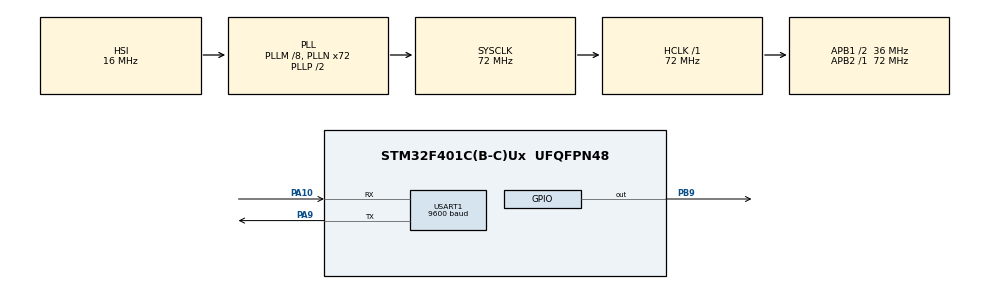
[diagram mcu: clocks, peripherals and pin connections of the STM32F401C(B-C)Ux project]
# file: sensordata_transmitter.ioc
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Mcu.Family=STM32F4
Mcu.Name=STM32F401C(B-C)Ux
Mcu.Package=UFQFPN48
NVIC.PriorityGroup=NVIC_PRIORITYGROUP_4
PA10.Mode=Asynchronous
PA10.Signal=USART1_RX
PA13.Mode=Serial_Wire
PA13.Signal=SYS_JTMS-SWDIO
PA14.Mode=Serial_Wire
PA14.Signal=SYS_JTCK-SWCLK
PA9.Mode=Asynchronous
PA9.Signal=USART1_TX
PB9.Signal=GPIO_Output
ProjectManager.HeapSize=0x200
ProjectManager.StackSize=0x400
ProjectManager.TargetToolchain=STM32CubeIDE
RCC.48MHZClocksFreq_Value=36000000
RCC.AHBFreq_Value=72000000
RCC.APB1CLKDivider=RCC_HCLK_DIV2
RCC.APB1Freq_Value=36000000
RCC.APB1TimFreq_Value=72000000
RCC.APB2Freq_Value=72000000
RCC.APB2TimFreq_Value=72000000
RCC.CortexFreq_Value=72000000
RCC.HCLKFreq_Value=72000000
RCC.HSE_VALUE=25000000
RCC.HSI_VALUE=16000000
RCC.LSE_VALUE=32768
RCC.PLLM=8
RCC.PLLN=72
RCC.SYSCLKFreq_VALUE=72000000
RCC.SYSCLKSource=RCC_SYSCLKSOURCE_PLLCLK
RCC.VCOOutputFreq_Value=144000000
TIM1.Prescaler=71
USART1.BaudRate=9600
USART1.VirtualMode=VM_ASYNC
VP_TIM1_VS_ClockSourceINT.Mode=Internal
board=custom

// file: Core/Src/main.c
/* USER CODE BEGIN Header */
/**
  ******************************************************************************
  * @file           : main.c
  * @brief          : Main program body
  ******************************************************************************
  * @attention
  *
  * Copyright (c) 2024 STMicroelectronics.
  * All rights reserved.
  *
  * This software is licensed under terms that can be found in the LICENSE file
  * in the root directory of this software component.
  * If no LICENSE file comes with this software, it is provided AS-IS.
  *
  ******************************************************************************
  */
/* USER CODE END Header */
#include "main.h"

/* USER CODE BEGIN Includes */
#include <stdio.h>
#include <string.h>
/* USER CODE END Includes */

TIM_HandleTypeDef htim1;

UART_HandleTypeDef huart1;

void SystemClock_Config(void);
static void MX_GPIO_Init(void);
static void MX_TIM1_Init(void);
static void MX_USART1_UART_Init(void);

/* USER CODE BEGIN 0 */
#define DHT11_PORT GPIOB
#define DHT11_PIN GPIO_PIN_9
uint8_t RHI, RHD, TCI, TCD, SUM;
uint32_t pMillis, cMillis;
float tCelsius = 0;
float tFahrenheit = 0;
float RH = 0;
uint8_t TFI = 0;
uint8_t TFD = 0;
char strCopy[20];

void microDelay (uint16_t delay)
{
  __HAL_TIM_SET_COUNTER(&htim1, 0);
  while (__HAL_TIM_GET_COUNTER(&htim1) < delay);
}

uint8_t DHT11_Start (void)
{
  uint8_t Response = 0;
  GPIO_InitTypeDef GPIO_InitStructPrivate = {0};
  GPIO_InitStructPrivate.Pin = DHT11_PIN;
  GPIO_InitStructPrivate.Mode = GPIO_MODE_OUTPUT_PP;
  GPIO_InitStructPrivate.Speed = GPIO_SPEED_FREQ_LOW;
  GPIO_InitStructPrivate.Pull = GPIO_NOPULL;
  HAL_GPIO_Init(DHT11_PORT, &GPIO_InitStructPrivate); // set the pin as output
  HAL_GPIO_WritePin (DHT11_PORT, DHT11_PIN, 0);   // pull the pin low
  HAL_Delay(20);   // wait for 20ms
  HAL_GPIO_WritePin (DHT11_PORT, DHT11_PIN, 1);   // pull the pin high
  microDelay (30);   // wait for 30us
  GPIO_InitStructPrivate.Mode = GPIO_MODE_INPUT;
  GPIO_InitStructPrivate.Pull = GPIO_PULLUP;
  HAL_GPIO_Init(DHT11_PORT, &GPIO_InitStructPrivate); // set the pin as input
  microDelay (40);
  if (!(HAL_GPIO_ReadPin (DHT11_PORT, DHT11_PIN)))
  {
    microDelay (80);
    if ((HAL_GPIO_ReadPin (DHT11_PORT, DHT11_PIN))) Response = 1;
  }
  pMillis = HAL_GetTick();
  cMillis = HAL_GetTick();
  while ((HAL_GPIO_ReadPin (DHT11_PORT, DHT11_PIN)) && pMillis + 2 > cMillis)
  {
    cMillis = HAL_GetTick();
  }
  return Response;
}

uint8_t DHT11_Read (void)
{
  uint8_t a,b;
  for (a=0;a<8;a++)
  {
    pMillis = HAL_GetTick();
    cMillis = HAL_GetTick();
    while (!(HAL_GPIO_ReadPin (DHT11_PORT, DHT11_PIN)) && pMillis + 2 > cMillis)
    {  // wait for the pin to go high
      cMillis = HAL_GetTick();
    }
    microDelay (40);   // wait for 40 us
    if (!(HAL_GPIO_ReadPin (DHT11_PORT, DHT11_PIN)))   // if the pin is low
      b&= ~(1<<(7-a));
    else
      b|= (1<<(7-a));
    pMillis = HAL_GetTick();
    cMillis = HAL_GetTick();
    while ((HAL_GPIO_ReadPin (DHT11_PORT, DHT11_PIN)) && pMillis + 2 > cMillis)
    {  // wait for the pin to go low
      cMillis = HAL_GetTick();
    }
  }
  return b;
}

void UART_SendData(UART_HandleTypeDef *huart, uint8_t *pData, uint16_t Size) {
    HAL_UART_Transmit(huart, pData, Size, HAL_MAX_DELAY);
}
void sendATCommand(UART_HandleTypeDef *huart, const char *command, char *response, uint16_t response_len) {
    HAL_UART_Transmit(huart, (uint8_t *)command, strlen(command), HAL_MAX_DELAY);
    HAL_UART_Receive(huart, (uint8_t *)response, response_len, HAL_MAX_DELAY);
}

/* USER CODE END 0 */

int main(void)
{

  /* USER CODE BEGIN 1 */
	 char response[100];

	    // HC05 configuration
	    sendATCommand(&huart1, "AT\r\n", response, sizeof(response)); // Test AT
	    HAL_Delay(1000);
	    sendATCommand(&huart1, "AT+ROLE=1\r\n", response, sizeof(response)); // Set to master mode
	    HAL_Delay(1000);
	    sendATCommand(&huart1, "AT+UART=9600,0,0\r\n", response, sizeof(response)); // Set baud rate
	    HAL_Delay(1000);
	    sendATCommand(&huart1, "AT+CMODE=0\r\n", response, sizeof(response)); // Pair with specific address
	    HAL_Delay(1000);
	    sendATCommand(&huart1, "AT+BIND=001122334455\r\n", response, sizeof(response)); // Replace with Tinysine address
	    HAL_Delay(1000);

	    // Send data from HC05 to Tinysine
	    const char *data = "Hello Tinysine!";
	    HAL_UART_Transmit(&huart1, (uint8_t *)data, strlen(data), HAL_MAX_DELAY);

  /* USER CODE END 1 */

  /* MCU Configuration--------------------------------------------------------*/

  /* Reset of all peripherals, Initializes the Flash interface and the Systick. */
  HAL_Init();

  /* Configure the system clock */
  SystemClock_Config();

  /* Initialize all configured peripherals */
  MX_GPIO_Init();
  MX_TIM1_Init();
  MX_USART1_UART_Init();
  /* USER CODE BEGIN 2 */
  HAL_TIM_Base_Start(&htim1);

  /* USER CODE END 2 */

  /* Infinite loop */
  /* USER CODE BEGIN WHILE */
  while (1)
  {
	  if(DHT11_Start())
	  	      {
	  	        RHI = DHT11_Read(); // Relative humidity integral
	  	        RHD = DHT11_Read(); // Relative humidity decimal
	  	        TCI = DHT11_Read(); // Celsius integral
	  	        TCD = DHT11_Read(); // Celsius decimal
	  	        SUM = DHT11_Read(); // Check sum

	  	        if (RHI + RHD + TCI + TCD == SUM)
	  	        {
	  	          // Can use RHI and TCI for any purposes if whole number only needed
	  	          tCelsius = (float)TCI + (float)(TCD/10.0);
	  	          tFahrenheit = tCelsius * 9/5 + 32;
	  	          RH = (float)RHI + (float)(RHD/10.0);
	  	          // Can use tCelsius, tFahrenheit and RH for any purposes
	  	          TFI = tFahrenheit;  // Fahrenheit integral
	  	          TFD = tFahrenheit*10-TFI*10; // Fahrenheit decimal
	  	          char teststring[128] = "Hello \n";
	  	          UART_SendData(&huart1, (uint8_t *)teststring, strlen(teststring));

	  	          sprintf(strCopy,"Temp: %d.%d C   \n", TCI, TCD);
	  	          UART_SendData(&huart1, (uint8_t *)strCopy, strlen(strCopy));

	  	          sprintf(strCopy,"RH: %d.%d %%   \n\n\n", RHI, RHD);
	  	          UART_SendData(&huart1, (uint8_t *)strCopy, strlen(strCopy));

	  	          microDelay(200);
	  	        }

	  	      }
	  	      HAL_Delay(1000);
    /* USER CODE END WHILE */

  }
}

void SystemClock_Config(void)
{
  RCC_OscInitTypeDef RCC_OscInitStruct = {0};
  RCC_ClkInitTypeDef RCC_ClkInitStruct = {0};

  /** Configure the main internal regulator output voltage
  */
  __HAL_RCC_PWR_CLK_ENABLE();
  __HAL_PWR_VOLTAGESCALING_CONFIG(PWR_REGULATOR_VOLTAGE_SCALE2);

  /** Initializes the RCC Oscillators according to the specified parameters
  * in the RCC_OscInitTypeDef structure.
  */
  RCC_OscInitStruct.OscillatorType = RCC_OSCILLATORTYPE_HSI;
  RCC_OscInitStruct.HSIState = RCC_HSI_ON;
  RCC_OscInitStruct.HSICalibrationValue = RCC_HSICALIBRATION_DEFAULT;
  RCC_OscInitStruct.PLL.PLLState = RCC_PLL_ON;
  RCC_OscInitStruct.PLL.PLLSource = RCC_PLLSOURCE_HSI;
  RCC_OscInitStruct.PLL.PLLM = 8;
  RCC_OscInitStruct.PLL.PLLN = 72;
  RCC_OscInitStruct.PLL.PLLP = RCC_PLLP_DIV2;
  RCC_OscInitStruct.PLL.PLLQ = 4;
  if (HAL_RCC_OscConfig(&RCC_OscInitStruct) != HAL_OK)
  {
    Error_Handler();
  }

  /** Initializes the CPU, AHB and APB buses clocks
  */
  RCC_ClkInitStruct.ClockType = RCC_CLOCKTYPE_HCLK|RCC_CLOCKTYPE_SYSCLK
                              |RCC_CLOCKTYPE_PCLK1|RCC_CLOCKTYPE_PCLK2;
  RCC_ClkInitStruct.SYSCLKSource = RCC_SYSCLKSOURCE_PLLCLK;
  RCC_ClkInitStruct.AHBCLKDivider = RCC_SYSCLK_DIV1;
  RCC_ClkInitStruct.APB1CLKDivider = RCC_HCLK_DIV2;
  RCC_ClkInitStruct.APB2CLKDivider = RCC_HCLK_DIV1;

  if (HAL_RCC_ClockConfig(&RCC_ClkInitStruct, FLASH_LATENCY_2) != HAL_OK)
  {
    Error_Handler();
  }
}

static void MX_TIM1_Init(void)
{

  TIM_ClockConfigTypeDef sClockSourceConfig = {0};
  TIM_MasterConfigTypeDef sMasterConfig = {0};

  htim1.Instance = TIM1;
  htim1.Init.Prescaler = 71;
  htim1.Init.CounterMode = TIM_COUNTERMODE_UP;
  htim1.Init.Period = 65535;
  htim1.Init.ClockDivision = TIM_CLOCKDIVISION_DIV1;
  htim1.Init.RepetitionCounter = 0;
  htim1.Init.AutoReloadPreload = TIM_AUTORELOAD_PRELOAD_DISABLE;
  if (HAL_TIM_Base_Init(&htim1) != HAL_OK)
  {
    Error_Handler();
  }
  sClockSourceConfig.ClockSource = TIM_CLOCKSOURCE_INTERNAL;
  if (HAL_TIM_ConfigClockSource(&htim1, &sClockSourceConfig) != HAL_OK)
  {
    Error_Handler();
  }
  sMasterConfig.MasterOutputTrigger = TIM_TRGO_RESET;
  sMasterConfig.MasterSlaveMode = TIM_MASTERSLAVEMODE_DISABLE;
  if (HAL_TIMEx_MasterConfigSynchronization(&htim1, &sMasterConfig) != HAL_OK)
  {
    Error_Handler();
  }

}

static void MX_USART1_UART_Init(void)
{

  huart1.Instance = USART1;
  huart1.Init.BaudRate = 9600;
  huart1.Init.WordLength = UART_WORDLENGTH_8B;
  huart1.Init.StopBits = UART_STOPBITS_1;
  huart1.Init.Parity = UART_PARITY_NONE;
  huart1.Init.Mode = UART_MODE_TX_RX;
  huart1.Init.HwFlowCtl = UART_HWCONTROL_NONE;
  huart1.Init.OverSampling = UART_OVERSAMPLING_16;
  if (HAL_UART_Init(&huart1) != HAL_OK)
  {
    Error_Handler();
  }

}

static void MX_GPIO_Init(void)
{
  GPIO_InitTypeDef GPIO_InitStruct = {0};

  /* GPIO Ports Clock Enable */
  __HAL_RCC_GPIOA_CLK_ENABLE();
  __HAL_RCC_GPIOB_CLK_ENABLE();

  /*Configure GPIO pin Output Level */
  HAL_GPIO_WritePin(GPIOB, GPIO_PIN_9, GPIO_PIN_RESET);

  /*Configure GPIO pin : PB9 */
  GPIO_InitStruct.Pin = GPIO_PIN_9;
  GPIO_InitStruct.Mode = GPIO_MODE_OUTPUT_PP;
  GPIO_InitStruct.Pull = GPIO_NOPULL;
  GPIO_InitStruct.Speed = GPIO_SPEED_FREQ_LOW;
  HAL_GPIO_Init(GPIOB, &GPIO_InitStruct);

}

void Error_Handler(void)
{
  __disable_irq();
  while (1)
  {
  }
}
